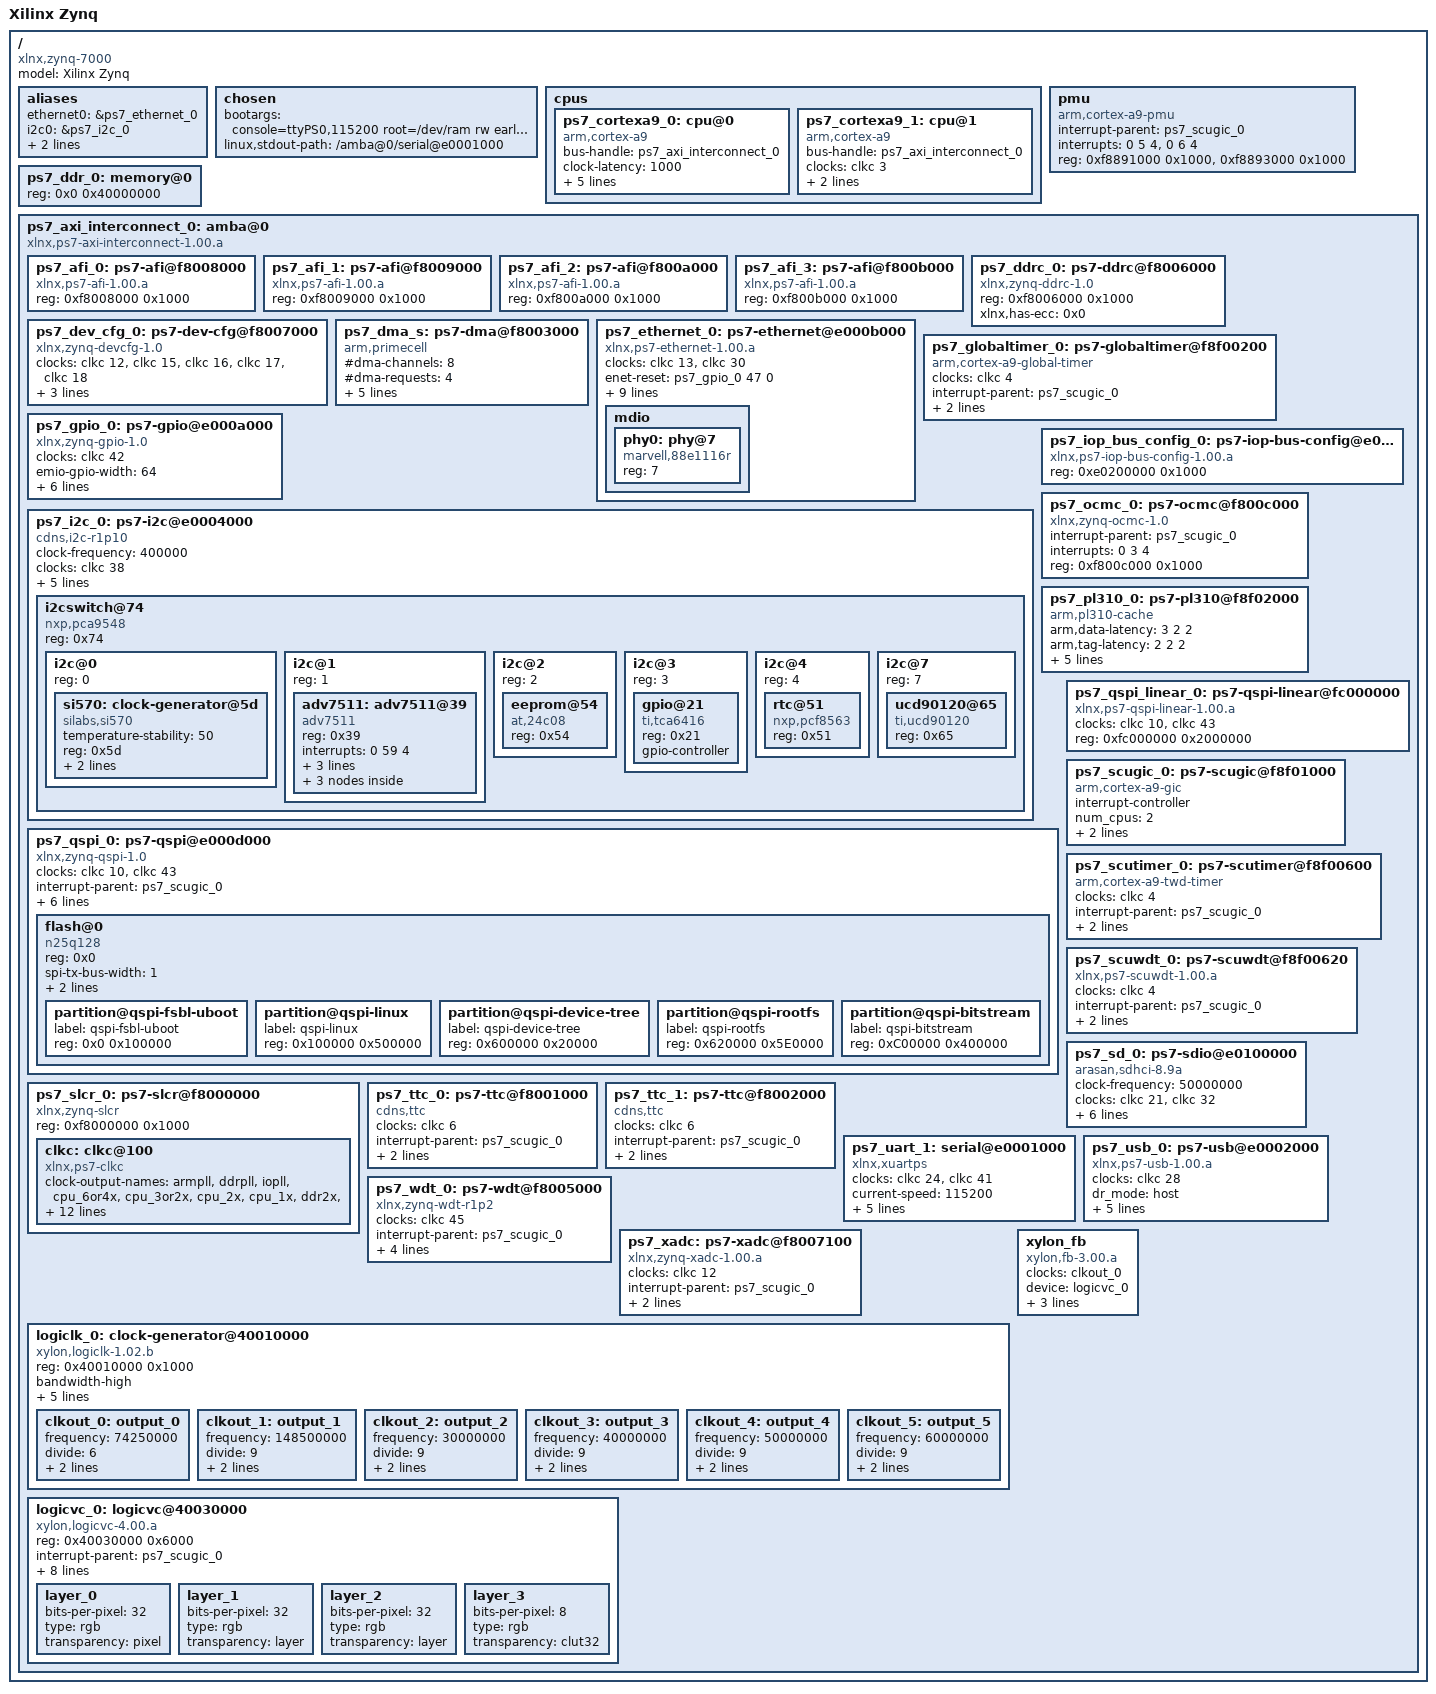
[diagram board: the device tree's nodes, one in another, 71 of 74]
/*
 * Device Tree Generator version: 1.1
 *
 * (C) Copyright 2007-2013 Xilinx, Inc.
 * (C) Copyright 2007-2013 Michal Simek
 * (C) Copyright 2007-2012 PetaLogix Qld Pty Ltd
 *
 * Michal SIMEK <monstr@monstr.eu>
 *
 * CAUTION: This file is automatically generated by libgen.
 * Version: Xilinx EDK 14.5 EDK_P.58f
 *
 */

/dts-v1/;
/ {
	#address-cells = <1>;
	#size-cells = <1>;
	compatible = "xlnx,zynq-7000";
	model = "Xilinx Zynq";
	aliases {
		ethernet0 = &ps7_ethernet_0;
		i2c0 = &ps7_i2c_0;
		serial0 = &ps7_uart_1;
		spi0 = &ps7_qspi_0;
	} ;
	chosen {
		bootargs = "console=ttyPS0,115200 root=/dev/ram rw earlyprintk";
		linux,stdout-path = "/amba@0/serial@e0001000";
	} ;
	cpus {
		#address-cells = <1>;
		#size-cells = <0>;
		ps7_cortexa9_0: cpu@0 {
			bus-handle = <&ps7_axi_interconnect_0>;
			clock-latency = <1000>;
			clocks = <&clkc 3>;
			compatible = "arm,cortex-a9";
			device_type = "cpu";
			interrupt-handle = <&ps7_scugic_0>;
			operating-points = <666667 1000000 333334 1000000 222223 1000000>;
			reg = <0x0>;
		} ;
		ps7_cortexa9_1: cpu@1 {
			bus-handle = <&ps7_axi_interconnect_0>;
			clocks = <&clkc 3>;
			compatible = "arm,cortex-a9";
			device_type = "cpu";
			interrupt-handle = <&ps7_scugic_0>;
			reg = <0x1>;
		} ;
	} ;
	pmu {
		compatible = "arm,cortex-a9-pmu";
		interrupt-parent = <&ps7_scugic_0>;
		interrupts = <0 5 4>, <0 6 4>;
		reg = <0xf8891000 0x1000>, <0xf8893000 0x1000>;
		reg-names = "cpu0", "cpu1";
	} ;
	ps7_ddr_0: memory@0 {
		device_type = "memory";
		reg = <0x0 0x40000000>;
	} ;
	ps7_axi_interconnect_0: amba@0 {
		#address-cells = <1>;
		#size-cells = <1>;
		compatible = "xlnx,ps7-axi-interconnect-1.00.a", "simple-bus";
		ranges ;
		ps7_afi_0: ps7-afi@f8008000 {
			compatible = "xlnx,ps7-afi-1.00.a";
			reg = <0xf8008000 0x1000>;
		} ;
		ps7_afi_1: ps7-afi@f8009000 {
			compatible = "xlnx,ps7-afi-1.00.a";
			reg = <0xf8009000 0x1000>;
		} ;
		ps7_afi_2: ps7-afi@f800a000 {
			compatible = "xlnx,ps7-afi-1.00.a";
			reg = <0xf800a000 0x1000>;
		} ;
		ps7_afi_3: ps7-afi@f800b000 {
			compatible = "xlnx,ps7-afi-1.00.a";
			reg = <0xf800b000 0x1000>;
		} ;
		ps7_ddrc_0: ps7-ddrc@f8006000 {
			compatible = "xlnx,zynq-ddrc-1.0";
			reg = <0xf8006000 0x1000>;
			xlnx,has-ecc = <0x0>;
		} ;
		ps7_dev_cfg_0: ps7-dev-cfg@f8007000 {
			clock-names = "ref_clk", "fclk0", "fclk1", "fclk2", "fclk3";
			clocks = <&clkc 12>, <&clkc 15>, <&clkc 16>, <&clkc 17>, <&clkc 18>;
			compatible = "xlnx,zynq-devcfg-1.0";
			interrupt-parent = <&ps7_scugic_0>;
			interrupts = <0 8 4>;
			reg = <0xf8007000 0x100>;
		} ;
		ps7_dma_s: ps7-dma@f8003000 {
			#dma-cells = <1>;
			#dma-channels = <8>;
			#dma-requests = <4>;
			clock-names = "apb_pclk";
			clocks = <&clkc 27>;
			compatible = "arm,primecell", "arm,pl330";
			interrupt-names = "abort", "dma0", "dma1", "dma2", "dma3",
				"dma4", "dma5", "dma6", "dma7";
			interrupt-parent = <&ps7_scugic_0>;
			interrupts = <0 13 4>, <0 14 4>, <0 15 4>, <0 16 4>, <0 17 4>, <0 40 4>, <0 41 4>, <0 42 4>, <0 43 4>;
			reg = <0xf8003000 0x1000>;
		} ;
		ps7_ethernet_0: ps7-ethernet@e000b000 {
			#address-cells = <1>;
			#size-cells = <0>;
			clock-names = "ref_clk", "aper_clk";
			clocks = <&clkc 13>, <&clkc 30>;
			compatible = "xlnx,ps7-ethernet-1.00.a";
			enet-reset = <&ps7_gpio_0 47 0>;
			interrupt-parent = <&ps7_scugic_0>;
			interrupts = <0 22 4>;
			local-mac-address = [00 0a 35 00 00 00];
			phy-handle = <&phy0>;
			phy-mode = "rgmii-id";
			reg = <0xe000b000 0x1000>;
			xlnx,eth-mode = <0x1>;
			xlnx,has-mdio = <0x1>;
			xlnx,ptp-enet-clock = <111111115>;
			mdio {
				#address-cells = <1>;
				#size-cells = <0>;
				phy0: phy@7 {
					compatible = "marvell,88e1116r";
					device_type = "ethernet-phy";
					reg = <7>;
				} ;
			} ;
		} ;
		ps7_globaltimer_0: ps7-globaltimer@f8f00200 {
			clocks = <&clkc 4>;
			compatible = "arm,cortex-a9-global-timer";
			interrupt-parent = <&ps7_scugic_0>;
			interrupts = <1 11 0x301>;
			reg = <0xf8f00200 0x100>;
		} ;
		ps7_gpio_0: ps7-gpio@e000a000 {
			#gpio-cells = <2>;
			clocks = <&clkc 42>;
			compatible = "xlnx,zynq-gpio-1.0";
			emio-gpio-width = <64>;
			gpio-controller ;
			gpio-mask-high = <0x0>;
			gpio-mask-low = <0x0>;
			interrupt-parent = <&ps7_scugic_0>;
			interrupts = <0 20 4>;
			reg = <0xe000a000 0x1000>;
		} ;
		ps7_i2c_0: ps7-i2c@e0004000 {
			clock-frequency = <400000>;
			clocks = <&clkc 38>;
			compatible = "cdns,i2c-r1p10";
			i2c-reset = <&ps7_gpio_0 46 0>;
			interrupt-parent = <&ps7_scugic_0>;
			interrupts = <0 25 4>;
			reg = <0xe0004000 0x1000>;
			xlnx,has-interrupt = <0x0>;
			#address-cells = <1>;
			#size-cells = <0>;
			i2cswitch@74 {
				compatible = "nxp,pca9548";
				#address-cells = <1>;
				#size-cells = <0>;
				reg = <0x74>;

				i2c@0 {
					#address-cells = <1>;
					#size-cells = <0>;
					reg = <0>;
					si570: clock-generator@5d {
						#clock-cells = <0>;
						compatible = "silabs,si570";
						temperature-stability = <50>;
						reg = <0x5d>;
						factory-fout = <156250000>;
						clock-frequency = <148500000>;
					};
				};

				i2c@1 {
					#address-cells = <1>;
					#size-cells = <0>;
					reg = <1>;
					adv7511: adv7511@39 {
						compatible = "adv7511";
						reg = <0x39>;
						interrupts = <0 59 4>;
						interrupt-parent = <&ps7_scugic_0>;
						dma-request = <&logicvc_0>;
						edid-addr = <0x50>;
						video-input {
							input-id = <0>;
							input-style = <0>;
							input-color-depth = <8>;
							bit-justification = <0>;
							hsync-polarity = <0>;
							vsync-polarity = <0>;
							clock-delay = <3>;
						};
						video-output {
							hdmi-mode = <0>;
							output-format = <0>;
							output-color-space = <0>;
							up-conversion = <0>;
							csc-enable = <0>;
							csc-scaling-factor = <2>;
							csc-coefficients {
								a1 = <0x0B37>;
								a2 = <0x0800>;
								a3 = <0x0000>;
								a4 = <0x1A86>;
								b1 = <0x1A49>;
								b2 = <0x0800>;
								b3 = <0x1D3F>;
								b4 = <0x0422>;
								c1 = <0x0000>;
								c2 = <0x0800>;
								c3 = <0x0E2D>;
								c4 = <0x1914>;
							};
						};
					};
				};

				i2c@2 {
					#address-cells = <1>;
					#size-cells = <0>;
					reg = <2>;
					eeprom@54 {
						compatible = "at,24c08";
						reg = <0x54>;
					};
				};

				i2c@3 {
					#address-cells = <1>;
					#size-cells = <0>;
					reg = <3>;
					gpio@21 {
						compatible = "ti,tca6416";
						reg = <0x21>;
						gpio-controller;
						#gpio-cells = <2>;
					};
				};

				i2c@4 {
					#address-cells = <1>;
					#size-cells = <0>;
					reg = <4>;
					rtc@51 {
						compatible = "nxp,pcf8563";
						reg = <0x51>;
					};
				};

				i2c@7 {
					#address-cells = <1>;
					#size-cells = <0>;
					reg = <7>;
					ucd90120@65 {
						compatible = "ti,ucd90120";
						reg = <0x65>;
					};
				};
			};

		} ;
		ps7_iop_bus_config_0: ps7-iop-bus-config@e0200000 {
			compatible = "xlnx,ps7-iop-bus-config-1.00.a";
			reg = <0xe0200000 0x1000>;
		} ;
		ps7_ocmc_0: ps7-ocmc@f800c000 {
			compatible = "xlnx,zynq-ocmc-1.0";
			interrupt-parent = <&ps7_scugic_0>;
			interrupts = <0 3 4>;
			reg = <0xf800c000 0x1000>;
		} ;
		ps7_pl310_0: ps7-pl310@f8f02000 {
			arm,data-latency = <3 2 2>;
			arm,tag-latency = <2 2 2>;
			cache-level = <2>;
			cache-unified ;
			compatible = "arm,pl310-cache";
			interrupt-parent = <&ps7_scugic_0>;
			interrupts = <0 2 4>;
			reg = <0xf8f02000 0x1000>;
		} ;
		ps7_qspi_0: ps7-qspi@e000d000 {
			clock-names = "ref_clk", "pclk";
			clocks = <&clkc 10>, <&clkc 43>;
			compatible = "xlnx,zynq-qspi-1.0";
			interrupt-parent = <&ps7_scugic_0>;
			interrupts = <0 19 4>;
			is-dual = <1>;
			num-cs = <1>;
			reg = <0xe000d000 0x1000>;
			xlnx,fb-clk = <0x1>;
			xlnx,qspi-mode = <0x2>;
			#address-cells = <1>;
			#size-cells = <0>;
			flash@0 {
				compatible = "n25q128";
				reg = <0x0>;
				spi-tx-bus-width = <1>;
				spi-rx-bus-width = <4>;
				spi-max-frequency = <50000000>;
				#address-cells = <1>;
				#size-cells = <1>;
				partition@qspi-fsbl-uboot {
					label = "qspi-fsbl-uboot";
					reg = <0x0 0x100000>;
				};
				partition@qspi-linux {
					label = "qspi-linux";
					reg = <0x100000 0x500000>;
				};
				partition@qspi-device-tree {
					label = "qspi-device-tree";
					reg = <0x600000 0x20000>;
				};
				partition@qspi-rootfs {
					label = "qspi-rootfs";
					reg = <0x620000 0x5E0000>;
				};
				partition@qspi-bitstream {
					label = "qspi-bitstream";
					reg = <0xC00000 0x400000>;
				};
			};

		} ;
		ps7_qspi_linear_0: ps7-qspi-linear@fc000000 {
			clock-names = "ref_clk", "aper_clk";
			clocks = <&clkc 10>, <&clkc 43>;
			compatible = "xlnx,ps7-qspi-linear-1.00.a";
			reg = <0xfc000000 0x2000000>;
		} ;
		ps7_scugic_0: ps7-scugic@f8f01000 {
			#address-cells = <2>;
			#interrupt-cells = <3>;
			#size-cells = <1>;
			compatible = "arm,cortex-a9-gic", "arm,gic";
			interrupt-controller ;
			num_cpus = <2>;
			num_interrupts = <96>;
			reg = <0xf8f01000 0x1000>, <0xf8f00100 0x100>;
		} ;
		ps7_scutimer_0: ps7-scutimer@f8f00600 {
			clocks = <&clkc 4>;
			compatible = "arm,cortex-a9-twd-timer";
			interrupt-parent = <&ps7_scugic_0>;
			interrupts = <1 13 0x301>;
			reg = <0xf8f00600 0x20>;
		} ;
		ps7_scuwdt_0: ps7-scuwdt@f8f00620 {
			clocks = <&clkc 4>;
			compatible = "xlnx,ps7-scuwdt-1.00.a";
			device_type = "watchdog";
			interrupt-parent = <&ps7_scugic_0>;
			interrupts = <1 14 0x301>;
			reg = <0xf8f00620 0xe0>;
		} ;
		ps7_sd_0: ps7-sdio@e0100000 {
			clock-frequency = <50000000>;
			clock-names = "clk_xin", "clk_ahb";
			clocks = <&clkc 21>, <&clkc 32>;
			compatible = "arasan,sdhci-8.9a";
			interrupt-parent = <&ps7_scugic_0>;
			interrupts = <0 24 4>;
			reg = <0xe0100000 0x1000>;
			xlnx,has-cd = <0x1>;
			xlnx,has-power = <0x0>;
			xlnx,has-wp = <0x1>;
		} ;
		ps7_slcr_0: ps7-slcr@f8000000 {
			#address-cells = <1>;
			#size-cells = <1>;
			compatible = "xlnx,zynq-slcr", "syscon";
			ranges ;
			reg = <0xf8000000 0x1000>;
			clkc: clkc@100 {
				#clock-cells = <1>;
				clock-output-names = "armpll", "ddrpll", "iopll", "cpu_6or4x", "cpu_3or2x",
					"cpu_2x", "cpu_1x", "ddr2x", "ddr3x", "dci",
					"lqspi", "smc", "pcap", "gem0", "gem1",
					"fclk0", "fclk1", "fclk2", "fclk3", "can0",
					"can1", "sdio0", "sdio1", "uart0", "uart1",
					"spi0", "spi1", "dma", "usb0_aper", "usb1_aper",
					"gem0_aper", "gem1_aper", "sdio0_aper", "sdio1_aper", "spi0_aper",
					"spi1_aper", "can0_aper", "can1_aper", "i2c0_aper", "i2c1_aper",
					"uart0_aper", "uart1_aper", "gpio_aper", "lqspi_aper", "smc_aper",
					"swdt", "dbg_trc", "dbg_apb";
				compatible = "xlnx,ps7-clkc";
				fclk-enable = <0xf>;
				ps-clk-frequency = <33333333>;
				reg = <0x100 0x100>;
			} ;
		} ;
		ps7_ttc_0: ps7-ttc@f8001000 {
			clocks = <&clkc 6>;
			compatible = "cdns,ttc";
			interrupt-names = "ttc0", "ttc1", "ttc2";
			interrupt-parent = <&ps7_scugic_0>;
			interrupts = <0 10 4>, <0 11 4>, <0 12 4>;
			reg = <0xf8001000 0x1000>;
		} ;
		ps7_ttc_1: ps7-ttc@f8002000 {
			clocks = <&clkc 6>;
			compatible = "cdns,ttc";
			interrupt-names = "ttc0", "ttc1", "ttc2";
			interrupt-parent = <&ps7_scugic_0>;
			interrupts = <0 37 4>, <0 38 4>, <0 39 4>;
			reg = <0xf8002000 0x1000>;
		} ;
		ps7_uart_1: serial@e0001000 {
			clock-names = "ref_clk", "aper_clk";
			clocks = <&clkc 24>, <&clkc 41>;
			compatible = "xlnx,xuartps";
			current-speed = <115200>;
			device_type = "serial";
			interrupt-parent = <&ps7_scugic_0>;
			interrupts = <0 50 4>;
			port-number = <0>;
			reg = <0xe0001000 0x1000>;
			xlnx,has-modem = <0x0>;
		} ;
		ps7_usb_0: ps7-usb@e0002000 {
			clocks = <&clkc 28>;
			compatible = "xlnx,ps7-usb-1.00.a", "xlnx,zynq-usb-1.00.a";
			dr_mode = "host";
			interrupt-parent = <&ps7_scugic_0>;
			interrupts = <0 21 4>;
			phy_type = "ulpi";
			reg = <0xe0002000 0x1000>;
			usb-reset = <&ps7_gpio_0 7 0>;
		} ;
		ps7_wdt_0: ps7-wdt@f8005000 {
			clocks = <&clkc 45>;
			compatible = "xlnx,zynq-wdt-r1p2";
			device_type = "watchdog";
			interrupt-parent = <&ps7_scugic_0>;
			interrupts = <0 9 1>;
			reg = <0xf8005000 0x1000>;
			reset = <0>;
			timeout-sec = <10>;
		} ;
		ps7_xadc: ps7-xadc@f8007100 {
			clocks = <&clkc 12>;
			compatible = "xlnx,zynq-xadc-1.00.a";
			interrupt-parent = <&ps7_scugic_0>;
			interrupts = <0 7 4>;
			reg = <0xf8007100 0x20>;
		} ;
		logiclk_0: clock-generator@40010000 {
			compatible = "xylon,logiclk-1.02.b";
			reg = <0x40010000 0x1000>;
			bandwidth-high;
			input-frequency = <100000000>;
			input-divide = <1>;
			input-multiply = <9>;
			input-phase = <0>;
			precise-output = <&clkout_0>;
			clkout_0: output_0 {
				#clock-cells = <0>;
				frequency = <74250000>;
				divide = <6>;
				duty = <50000>;
				phase = <0>;
			};
			clkout_1: output_1 {
				#clock-cells = <0>;
				frequency = <148500000>;
				divide = <9>;
				duty = <50000>;
				phase = <0>;
			};
			clkout_2: output_2 {
				#clock-cells = <0>;
				frequency = <30000000>;
				divide = <9>;
				duty = <50000>;
				phase = <0>;
			};
			clkout_3: output_3 {
				#clock-cells = <0>;
				frequency = <40000000>;
				divide = <9>;
				duty = <50000>;
				phase = <0>;
			};
			clkout_4: output_4 {
				#clock-cells = <0>;
				frequency = <50000000>;
				divide = <9>;
				duty = <50000>;
				phase = <0>;
			};
			clkout_5: output_5 {
				#clock-cells = <0>;
				frequency = <60000000>;
				divide = <9>;
				duty = <50000>;
				phase = <0>;
			};
		} ;
		logicvc_0: logicvc@40030000 {
			compatible = "xylon,logicvc-4.00.a";
			reg = <0x40030000 0x6000>;
			interrupt-parent = <&ps7_scugic_0>;
			interrupts = <0 58 4>;
			background-layer-bits-per-pixel = <32>;
			background-layer-type = "rgb";
			hsync-active-low;
			vsync-active-low;
			readable-regs;
			size-position;
			pixel-stride = <2048>;
			layer_0 {
				bits-per-pixel = <32>;
				type = "rgb";
				transparency = "pixel";
			};
			layer_1 {
				bits-per-pixel = <32>;
				type = "rgb";
				transparency = "layer";
			};
			layer_2 {
				bits-per-pixel = <32>;
				type = "rgb";
				transparency = "layer";
			};
			layer_3 {
				bits-per-pixel = <8>;
				type = "rgb";
				transparency = "clut32";
			};
		} ;
		xylon_fb {
			compatible = "xylon,fb-3.00.a";
			clocks = <&clkout_0>;
			device = <&logicvc_0>;
			console-layer = <3>;
			vsync-irq;
			video-mode = "1024x768";
		} ;
	} ;
} ;
